# STM32MP13xx register map
File version: 1.5
CPU: CA7 r0p0, little endian, MPU, FPU, 4 interrupt priority bits
Registers are 32-bit, read-write, reset 0x0 unless marked. A register's access mark holds for its fields unless they carry their own. Offsets are from the block's base; [hi:lo] are bit positions; {n}, {i} and the like mark numbered series.

## LPTIM1 — LPTIM
Base 0x40009000
Same registers: LPTIM2 0x50021000, LPTIM3 0x50022000, LPTIM4 0x50023000, LPTIM5 0x50024000
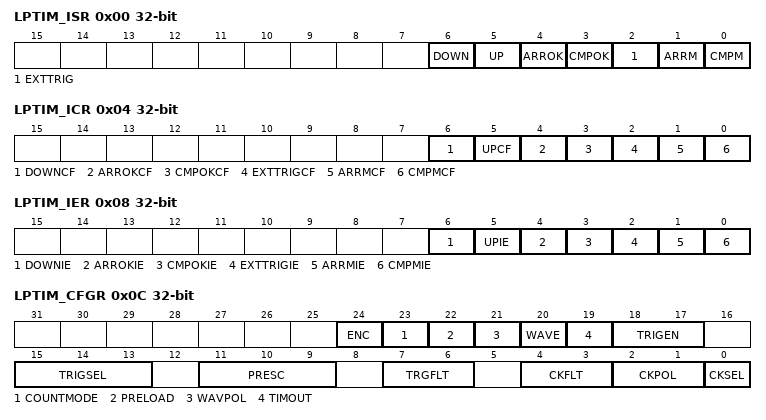
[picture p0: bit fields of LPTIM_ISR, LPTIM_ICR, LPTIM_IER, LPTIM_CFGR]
0x00 LPTIM_ISR ro — LPTIM interrupt and status register
  [6] DOWN — Counter direction change up to down In Encoder mode, DOWN bit is set by hardware to inform application that the counter direction has changed from up to down. DOWN flag can be cleared by writing 1 to the DOWNCF bit in the LPTIM_ICR register. Note: If the LPTIM does not support encoder mode feature, this bit is reserved. Please refer to .
  [5] UP — Counter direction change down to up In Encoder mode, UP bit is set by hardware to inform application that the counter direction has changed from down to up. UP flag can be cleared by writing 1 to the UPCF bit in the LPTIM_ICR register. Note: If the LPTIM does not support encoder mode feature, this bit is reserved. Please refer to .
  [4] ARROK — Autoreload register update OK ARROK is set by hardware to inform application that the APB bus write operation to the LPTIM_ARR register has been successfully completed. ARROK flag can be cleared by writing 1 to the ARROKCF bit in the LPTIM_ICR register.
  [3] CMPOK — Compare register update OK CMPOK is set by hardware to inform application that the APB bus write operation to the LPTIM_CMP register has been successfully completed.
  [2] EXTTRIG — External trigger edge event EXTTRIG is set by hardware to inform application that a valid edge on the selected external trigger input has occurred. If the trigger is ignored because the timer has already started, then this flag is not set. EXTTRIG flag can be cleared by writing 1 to the EXTTRIGCF bit in the LPTIM_ICR register.
  [1] ARRM — Autoreload match ARRM is set by hardware to inform application that LPTIM_CNT registerâs value reached the LPTIM_ARR registerâs value. ARRM flag can be cleared by writing 1 to the ARRMCF bit in the LPTIM_ICR register.
  [0] CMPM — Compare match The CMPM bit is set by hardware to inform application that LPTIM_CNT register value reached the LPTIM_CMP registerâs value.
0x04 LPTIM_ICR wo — LPTIM interrupt clear register
  [6] DOWNCF — Direction change to down clear flag Writing 1 to this bit clear the DOWN flag in the LPTIM_ISR register. Note: If the LPTIM does not support encoder mode feature, this bit is reserved. Please refer to .
  [5] UPCF — Direction change to UP clear flag Writing 1 to this bit clear the UP flag in the LPTIM_ISR register. Note: If the LPTIM does not support encoder mode feature, this bit is reserved. Please refer to .
  [4] ARROKCF — Autoreload register update OK clear flag Writing 1 to this bit clears the ARROK flag in the LPTIM_ISR register
  [3] CMPOKCF — Compare register update OK clear flag Writing 1 to this bit clears the CMPOK flag in the LPTIM_ISR register
  [2] EXTTRIGCF — External trigger valid edge clear flag Writing 1 to this bit clears the EXTTRIG flag in the LPTIM_ISR register
  [1] ARRMCF — Autoreload match clear flag Writing 1 to this bit clears the ARRM flag in the LPTIM_ISR register
  [0] CMPMCF — Compare match clear flag Writing 1 to this bit clears the CMPM flag in the LPTIM_ISR register
0x08 LPTIM_IER — LPTIM interrupt enable register
  [6] DOWNIE — Direction change to down Interrupt Enable Note: If the LPTIM does not support encoder mode feature, this bit is reserved. Please refer to .
    0=DOWN interrupt disabled; 1=DOWN interrupt enabled
  [5] UPIE — Direction change to UP Interrupt Enable Note: If the LPTIM does not support encoder mode feature, this bit is reserved. Please refer to .
    0=UP interrupt disabled; 1=UP interrupt enabled
  [4] ARROKIE — Autoreload register update OK Interrupt Enable
    0=ARROK interrupt disabled; 1=ARROK interrupt enabled
  [3] CMPOKIE — Compare register update OK Interrupt Enable
    0=CMPOK interrupt disabled; 1=CMPOK interrupt enabled
  [2] EXTTRIGIE — External trigger valid edge Interrupt Enable
    0=EXTTRIG interrupt disabled; 1=EXTTRIG interrupt enabled
  [1] ARRMIE — Autoreload match Interrupt Enable
    0=ARRM interrupt disabled; 1=ARRM interrupt enabled
  [0] CMPMIE — Compare match Interrupt Enable
    0=CMPM interrupt disabled; 1=CMPM interrupt enabled
0x0C LPTIM_CFGR — LPTIM configuration register
  [24] ENC — Encoder mode enable The ENC bit controls the Encoder mode Note: If the LPTIM does not support encoder mode feature, this bit is reserved. Please refer to .
    0=Encoder mode disabled; 1=Encoder mode enabled
  [23] COUNTMODE — counter mode enabled The COUNTMODE bit selects which clock source is used by the LPTIM to clock the counter:
    0=the counter is incremented following each internal clock pulse; 1=the counter is incremented following each valid clock pulse on the LPTIM external Input1
  [22] PRELOAD — Registers update mode The PRELOAD bit controls the LPTIM_ARR and the LPTIM_CMP registers update modality
    0=Registers are updated after each APB bus write access; 1=Registers are updated at the end of the current LPTIM period
  [21] WAVPOL — Waveform shape polarity The WAVEPOL bit controls the output polarity
    0=The LPTIM output reflects the compare results between LPTIM_CNT and LPTIM_CMP registers; 1=The LPTIM output reflects the inverse of the compare results between LPTIM_CNT and LPTIM_CMP registers
  [20] WAVE — Waveform shape The WAVE bit controls the output shape
    0=Deactivate Set-once mode, PWM or One Pulse waveform depending on how the timer was started, CNTSTRT for PWM or SNGSTRT for One Pulse waveform; 1=Activate the Set-once mode
  [19] TIMOUT — Timeout enable The TIMOUT bit controls the Timeout feature
    0=A trigger event arriving when the timer is already started will be ignored; 1=A trigger event arriving when the timer is already started will reset and restart the counter
  [18:17] TRIGEN — Trigger enable and polarity The TRIGEN bits controls whether the LPTIM counter is started by an external trigger or not. If the external trigger option is selected, three configurations are possible for the trigger active edge:
    0=software trigger (counting start is initiated by software); 1=rising edge is the active edge; 2=falling edge is the active edge; 3=both edges are active edges
  [15:13] TRIGSEL — Trigger selector The TRIGSEL bits select the trigger source that will serve as a trigger event for the LPTIM among the below 8 available sources: See for details.
    {v}=lptim_ext_trig{v} (v=0..7)
  [11:9] PRESC — Clock prescaler The PRESC bits configure the prescaler division factor. It can be one among the following division factors:
    0=/1; 1=/2; 2=/4; 3=/8; 4=/16; 5=/32; 6=/64; 7=/128
  [7:6] TRGFLT — Configurable digital filter for trigger The TRGFLT value sets the number of consecutive equal samples that should be detected when a level change occurs on an internal trigger before it is considered as a valid level transition. An internal clock source must be present to use this feature
    0=any trigger active level change is considered as a valid trigger; 1=trigger active level change must be stable for at least 2 clock periods before it is considered as valid trigger; 2=trigger active level change must be stable for at least 4 clock periods before it is considered as valid trigger; 3=trigger active level change must be stable for at least 8 clock periods before it is considered as valid trigger
  [4:3] CKFLT — Configurable digital filter for external clock The CKFLT value sets the number of consecutive equal samples that should be detected when a level change occurs on an external clock signal before it is considered as a valid level transition. An internal clock source must be present to use this feature
    0=any external clock signal level change is considered as a valid transition; 1=external clock signal level change must be stable for at least 2 clock periods before it is considered as valid transition; 2=external clock signal level change must be stable for at least 4 clock periods before it is considered as valid transition; 3=external clock signal level change must be stable for at least 8 clock periods before it is considered as valid transition
  [2:1] CKPOL — Clock Polarity If LPTIM is clocked by an external clock source: When the LPTIM is clocked by an external clock source, CKPOL bits is used to configure the active edge or edges used by the counter: If the LPTIM is configured in Encoder mode (ENC bit is set), the encoder sub-mode 1 is active. If the LPTIM is configured in Encoder mode (ENC bit is set), the encoder sub-mode 2 is active. Refer to for more details about Encoder mode sub-modes.
    0=the rising edge is the active edge used for counting; 1=the falling edge is the active edge used for counting; 2=both edges are active edges. When both external clock signal edges are considered active ones, the LPTIM must also be clocked by an internal clock source with a frequency equal to at least four times the external clock frequency.If the LPTIM is configured in Encoder mode (ENC bit is set), the encoder sub-mode 3 is active.; 3=not allowed
  [0] CKSEL — Clock selector The CKSEL bit selects which clock source the LPTIM will use:
    0=LPTIM is clocked by internal clock source (APB clock or any of the embedded oscillators); 1=LPTIM is clocked by an external clock source through the LPTIM external Input1
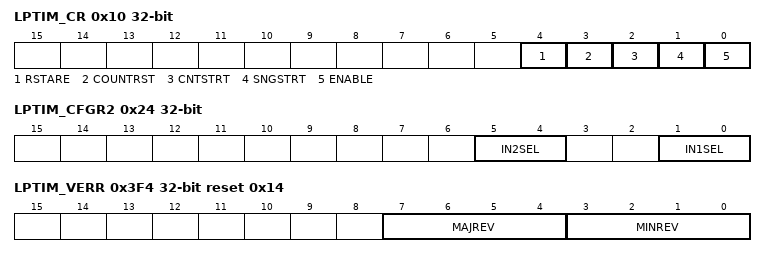
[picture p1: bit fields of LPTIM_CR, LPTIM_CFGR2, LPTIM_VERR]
0x10 LPTIM_CR — LPTIM control register
  [4] RSTARE — Reset after read enable This bit is set and cleared by software. When RSTARE is set to '1', any read access to LPTIM_CNT register will asynchronously reset LPTIM_CNT register content.
  [3] COUNTRST — Counter reset This bit is set by software and cleared by hardware. When set to '1' this bit will trigger a synchronous reset of the LPTIM_CNT counter register. Due to the synchronous nature of this reset, it only takes place after a synchronization delay of 3 LPTimer core clock cycles (LPTimer core clock may be different from APB clock). COUNTRST must never be set to '1' by software before it is already cleared to '0' by hardware. Software should consequently check that COUNTRST bit is already cleared to '0' before attempting to set it to '1'.
  [2] CNTSTRT — Timer start in Continuous mode This bit is set by software and cleared by hardware. In case of software start (TRIGEN[1:0] = '00â), setting this bit starts the LPTIM in Continuous mode. If the software start is disabled (TRIGEN[1:0] different than '00â), setting this bit starts the timer in Continuous mode as soon as an external trigger is detected. If this bit is set when a single pulse mode counting is ongoing, then the timer will not stop at the next match between the LPTIM_ARR and LPTIM_CNT registers and the LPTIM counter keeps counting in Continuous mode. This bit can be set only when the LPTIM is enabled. It will be automatically reset by hardware.
  [1] SNGSTRT — LPTIM start in Single mode This bit is set by software and cleared by hardware. In case of software start (TRIGEN[1:0] = '00â), setting this bit starts the LPTIM in single pulse mode. If the software start is disabled (TRIGEN[1:0] different than '00â), setting this bit starts the LPTIM in single pulse mode as soon as an external trigger is detected. If this bit is set when the LPTIM is in continuous counting mode, then the LPTIM will stop at the following match between LPTIM_ARR and LPTIM_CNT registers. This bit can only be set when the LPTIM is enabled. It will be automatically reset by hardware.
  [0] ENABLE — LPTIM enable The ENABLE bit is set and cleared by software.
    0=LPTIM is disabled; 1=LPTIM is enabled
0x14 LPTIM_CMP — LPTIM compare register
  [15:0] CMP — Compare value CMP is the compare value used by the LPTIM.
0x18 LPTIM_ARR reset 0x1 — LPTIM autoreload register
  [15:0] ARR — Auto reload value ARR is the autoreload value for the LPTIM. This value must be strictly greater than the CMP[15:0] value.
0x1C LPTIM_CNT ro — LPTIM counter register
  [15:0] CNT — Counter value When the LPTIM is running with an asynchronous clock, reading the LPTIM_CNT register may return unreliable values. So in this case it is necessary to perform two consecutive read accesses and verify that the two returned values are identical. It should be noted that for a reliable LPTIM_CNT register read access, two consecutive read accesses must be performed and compared. A read access can be considered reliable when the values of the two consecutive read accesses are equal.
0x24 LPTIM_CFGR2 — LPTIM configuration register 2
  [5:4] IN2SEL — LPTIM input 2 selection The IN2SEL bits control the LPTIM Input 2 multiplexer, which connect LPTIM Input 2 to one of the available inputs. For connection details refer to . Note: If the LPTIM does not support encoder mode feature, these bits are reserved. Please refer to .
    {v}=lptim_in2_mux{v} (v=0..3)
  [1:0] IN1SEL — LPTIM input 1 selection The IN1SEL bits control the LPTIM Input 1 multiplexer, which connects LPTIM Input 1 to one of the available inputs. For connection details refer to . Note: If LPTIM does not implement external input clock, these bits are reserved. Please refer to .
    {v}=lptim_in1_mux{v} (v=0..3)
0x3F4 LPTIM_VERR ro reset 0x14 — LPTIM peripheral version identification register
  [7:4] MAJREV — Major revision This is read only bit-field and is read as MAJREV[7:4] = 1.
  [3:0] MINREV — Minor revision This is a read only bit-field and is read as MINREV[3:0] = 4.
0x3F8 LPTIM_PIDR ro reset 0x120011 — LPTIM peripheral type identification register
  [31:0] P_ID — Peripheral type identifier This a read only register and is always read as P_ID[31:0] = 0x00120011.
0x3FC LPTIM_SIDR ro reset 0xA3C5DD01 — LPTIM registers map size identification register
  [31:0] S_ID — Registers map size identifier This a read only register and is always read as S_ID[31:0] = 0xA3C5DD01. This register identifies the size of the memory region allocated to the LPTIM registers. The size of this memory region is 1Â KB.
